# FSS_OSPI0_ECC_AGGR_53807000h register map
Vendor: Texas Instruments
Peripheral module from a debugger description file (folder AM261x).
Registers are 32-bit, access not given, reset 0x0 unless marked. A register's access mark holds for its fields unless they carry their own. Offsets are as the file gives them; lines under a group give offsets from that group; [hi:lo] are bit positions; {n}, {i} and the like mark numbered series; 'fields as' and 'values as' point back to an identical list; <NAME> marks a mode.

## OSPI0_ECC_AGGR
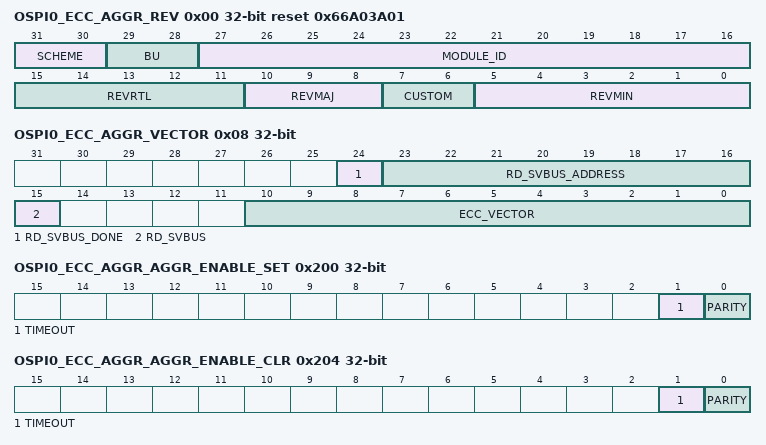
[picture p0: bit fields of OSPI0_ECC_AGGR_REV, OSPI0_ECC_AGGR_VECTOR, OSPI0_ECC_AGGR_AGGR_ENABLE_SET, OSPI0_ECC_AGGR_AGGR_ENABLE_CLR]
0x00 OSPI0_ECC_AGGR_REV ro reset 0x66A03A01 — Revision parameters.
  [31:30] SCHEME
  [29:28] BU
  [27:16] MODULE_ID
  [15:11] REVRTL — RTL version
  [10:8] REVMAJ — Major version
  [7:6] CUSTOM — Custom version
  [5:0] REVMIN — Minor version
0x08 OSPI0_ECC_AGGR_VECTOR — ECC Vector Register.
  [24] RD_SVBUS_DONE — Status to indicate if read on serial VBUS is complete, write of any value will clear this bit. (access R/W1TC)
  [23:16] RD_SVBUS_ADDRESS rw — Read address
  [15] RD_SVBUS — Write 1 to trigger a read on the serial VBUS (access R/W1TS)
  [10:0] ECC_VECTOR rw — Value written to select the corresponding ECC RAM for control or status
0x0C OSPI0_ECC_AGGR_STAT ro reset 0x1 — Misc Status.
  [10:0] NUM_RAMS — Indicates the number of RAMS serviced by the ECC aggregator
0x10 OSPI0_ECC_AGGR_RESERVED_SVBUS_j rw — Reference other documents that contain the ECC RAM wrapper and EDC controller serial vbus register sets.
  [31:0] DATA — Serial VBUS register data
0x3C OSPI0_ECC_AGGR_SEC_EOI_REG — EOI Register.
  [0] EOI_WR — EOI Register (access R/W1TS)
0x40 OSPI0_ECC_AGGR_SEC_STATUS_REG0 — Interrupt Status Register 0
  [0] SRAM_PEND — Interrupt Pending Status for sram_pend (access R/W1TS)
0x80 OSPI0_ECC_AGGR_SEC_ENABLE_SET_REG0 — Interrupt Enable Set Register 0
  [0] SRAM_ENABLE_SET — Interrupt Enable Set Register for sram_pend (access R/W1TS)
0xC0 OSPI0_ECC_AGGR_SEC_ENABLE_CLR_REG0 — Interrupt Enable Clear Register 0
  [0] SRAM_ENABLE_CLR — Interrupt Enable Clear Register for sram_pend (access R/W1TC)
0x13C OSPI0_ECC_AGGR_DED_EOI_REG — EOI Register.
  [0] EOI_WR — EOI Register (access R/W1TS)
0x140 OSPI0_ECC_AGGR_DED_STATUS_REG0 — Interrupt Status Register 0
  fields as OSPI0_ECC_AGGR_SEC_STATUS_REG0
0x180 OSPI0_ECC_AGGR_DED_ENABLE_SET_REG0 — Interrupt Enable Set Register 0
  fields as OSPI0_ECC_AGGR_SEC_ENABLE_SET_REG0
0x1C0 OSPI0_ECC_AGGR_DED_ENABLE_CLR_REG0 — Interrupt Enable Clear Register 0
  fields as OSPI0_ECC_AGGR_SEC_ENABLE_CLR_REG0
0x200 OSPI0_ECC_AGGR_AGGR_ENABLE_SET — AGGR interrupt enable set Register.
  [1] TIMEOUT — Interrupt enable set for svbus timeout errors (access R/W1TS)
  [0] PARITY — Interrupt enable set for parity errors (access R/W1TS)
0x204 OSPI0_ECC_AGGR_AGGR_ENABLE_CLR — AGGR interrupt enable clear Register.
  [1] TIMEOUT — Interrupt enable clear for svbus timeout errors (access R/W1TC)
  [0] PARITY — Interrupt enable clear for parity errors (access R/W1TC)
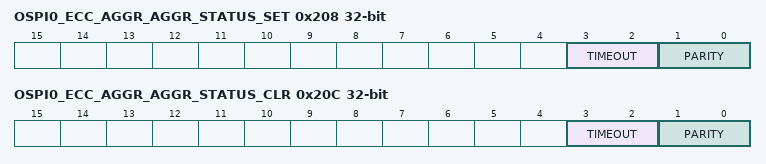
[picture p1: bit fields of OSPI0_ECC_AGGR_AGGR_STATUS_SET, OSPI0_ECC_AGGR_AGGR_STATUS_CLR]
0x208 OSPI0_ECC_AGGR_AGGR_STATUS_SET — AGGR interrupt status set Register.
  [3:2] TIMEOUT — Interrupt status set for svbus timeout errors (access R/WI)
  [1:0] PARITY — Interrupt status set for parity errors (access R/WI)
0x20C OSPI0_ECC_AGGR_AGGR_STATUS_CLR — AGGR interrupt status clear Register.
  [3:2] TIMEOUT — Interrupt status clear for svbus timeout errors (access R/WD)
  [1:0] PARITY — Interrupt status clear for parity errors (access R/WD)
